# STM32MP21_CA35 register map
File version: 0.4
CPU: CM33 r0p1, little endian, MPU, FPU, vendor SysTick, 8 interrupt priority bits
Registers are 32-bit, read-write, reset 0x0 unless marked. A register's access mark holds for its fields unless they carry their own. Offsets are from the block's base; [hi:lo] are bit positions; {n}, {i} and the like mark numbered series; 'fields as' and 'values as' point back to an identical list.

## EXTI1 — EXTI1 address block description
Base 0x44220000
Same registers: EXTI1_S 0x54220000
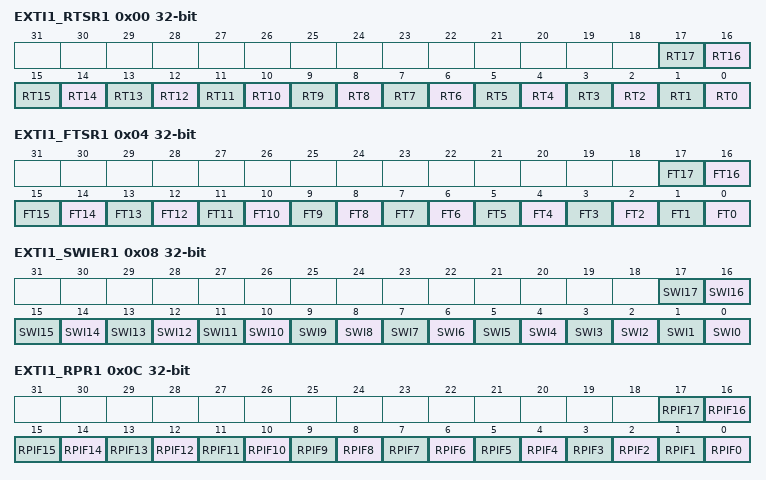
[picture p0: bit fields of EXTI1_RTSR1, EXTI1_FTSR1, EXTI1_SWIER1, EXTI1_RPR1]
0x00 EXTI1_RTSR1 — EXTI1 rising trigger selection register
  [all] fields
    0=Rising trigger disabled (for event and interrupt) for input line; 1=Rising trigger enabled (for event and interrupt) for input line
  [n] RT{n} (n=0..17) — Rising trigger event configuration bit of configurable event input x
0x04 EXTI1_FTSR1 — EXTI1 falling trigger selection register
  [all] fields
    0=Falling trigger disabled (for event and interrupt) for input line; 1=Falling trigger enabled (for event and interrupt) for input line
  [n] FT{n} (n=0..17) — Falling trigger event configuration bit of configurable event input x
0x08 EXTI1_SWIER1 — EXTI1 software interrupt event register
  [all] fields
    0=Writing 0 has no effect; 1=Writing 1 to this bit triggers a rising edge event on event x (bit auto cleared byhardware)
  [n] SWI{n} (n=0..17) — Software interrupt on event x
0x0C EXTI1_RPR1 — EXTI1 rising edge pending register
  [all] fields
    0=No rising edge trigger request occurred; 1=Rising edge trigger request occurred
  [n] RPIF{n} (n=0..17) — Configurable event input x rising edge pending bit
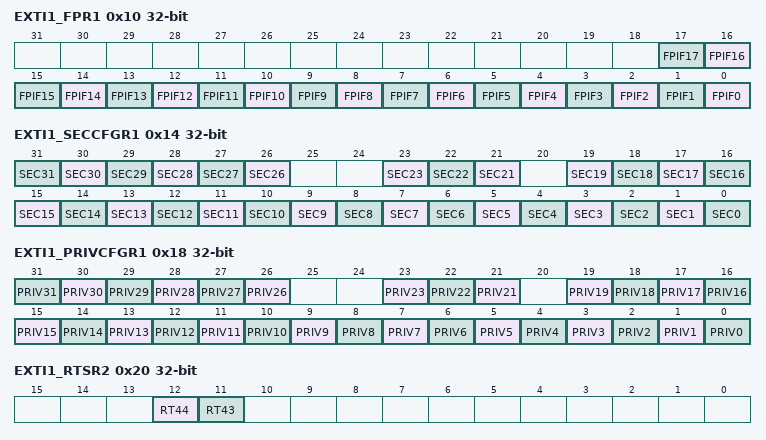
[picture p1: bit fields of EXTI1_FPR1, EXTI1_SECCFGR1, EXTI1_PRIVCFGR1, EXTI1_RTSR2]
0x10 EXTI1_FPR1 — EXTI1 falling edge pending register
  [all] fields
    0=No falling edge trigger request occurred; 1=Falling edge trigger request occurred
  [n] FPIF{n} (n=0..17) — configurable event input x falling edge pending bit
0x14 EXTI1_SECCFGR1 — EXTI1 security configuration register
  [n] SEC{n} (n=26..31) — Security enable on event input x
    0=Event security disabled (non-secure); 1=Event security enabled (secure)
  [23] SEC23 — Security enable on event input x
  [22] SEC22 — Security enable on event input x
  [21] SEC21 — Security enable on event input x
  [n] SEC{n} (n=0..19) — Security enable on event input x
0x18 EXTI1_PRIVCFGR1 — EXTI1 privilege configuration register
  [n] PRIV{n} (n=26..31) — Privilege enable on event input x
    0=Event privilege disabled (unprivileged); 1=Event privilege enabled (privileged)
  [23] PRIV23 — Privilege enable on event input x
  [22] PRIV22 — Privilege enable on event input x
  [21] PRIV21 — Privilege enable on event input x
  [n] PRIV{n} (n=0..19) — Privilege enable on event input x
0x20 EXTI1_RTSR2 — EXTI1 rising trigger selection register
  [12] RT44 — Rising trigger event configuration bit of configurable event input x
    0=Rising trigger disabled (for event and Interrupt) for input line x; 1=Rising trigger enabled (for event and Interrupt) for input line x
  [11] RT43 — Rising trigger event configuration bit of configurable event input x
    values as RT44
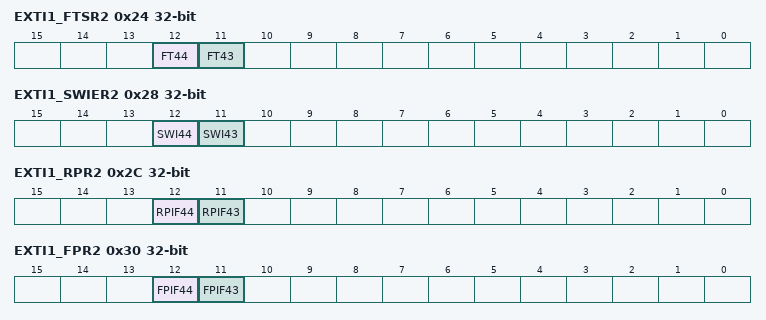
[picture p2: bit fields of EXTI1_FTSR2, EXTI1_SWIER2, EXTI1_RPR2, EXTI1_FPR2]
0x24 EXTI1_FTSR2 — EXTI1 falling trigger selection register
  [12] FT44 — Falling trigger event configuration bit of configurable event input x
    0=Falling trigger disabled (for event and Interrupt) for input line; 1=Falling trigger enabled (for event and Interrupt) for input line
  [11] FT43 — Falling trigger event configuration bit of configurable event input x
    values as FT44
0x28 EXTI1_SWIER2 — EXTI1 software interrupt event register
  [12] SWI44 — Software interrupt on event x
    0=Writing 0 has no effect; 1=Writing 1 to this bit triggers a rising edge event on event x (bit auto cleared by hardware)
  [11] SWI43 — Software interrupt on event x
    values as SWI44
0x2C EXTI1_RPR2 — EXTI1 rising edge pending register
  [12] RPIF44 — Configurable event input x rising edge pending bit
    values as the fields of EXTI1_RPR1
  [11] RPIF43 — Configurable event input x rising edge pending bit
    values as the fields of EXTI1_RPR1
0x30 EXTI1_FPR2 — EXTI1 falling edge pending register
  [12] FPIF44 — Configurable event input x falling edge pending bit
    values as the fields of EXTI1_FPR1
  [11] FPIF43 — Configurable event input x falling edge pending bit
    values as the fields of EXTI1_FPR1
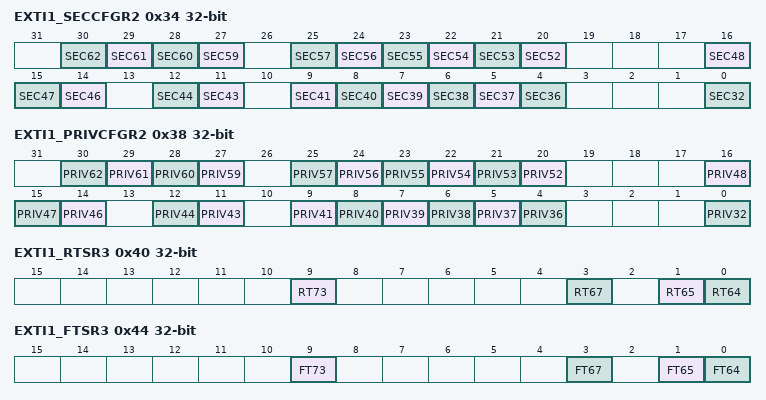
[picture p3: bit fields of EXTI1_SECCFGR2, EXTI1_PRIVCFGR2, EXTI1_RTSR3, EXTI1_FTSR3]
0x34 EXTI1_SECCFGR2 — EXTI1 security enable register
  [n-32] SEC{n} (n=59..62) — Security enable on event input x
    values as EXTI1_SECCFGR1.SEC26
  [n-32] SEC{n} (n=52..57) — Security enable on event input x
  [16] SEC48 — Security enable on event input x
  [15] SEC47 — Security enable on event input x
  [14] SEC46 — Security enable on event input x
  [12] SEC44 — Security enable on event input x
  [11] SEC43 — Security enable on event input x
  [n-32] SEC{n} (n=36..41) — Security enable on event input x
  [0] SEC32 — Security enable on event input 32
0x38 EXTI1_PRIVCFGR2 — EXTI1 privilege enable register
  [n-32] PRIV{n} (n=59..62) — Privilege enable on event input x
    values as EXTI1_PRIVCFGR1.PRIV26
  [n-32] PRIV{n} (n=52..57) — Privilege enable on event input x
  [16] PRIV48 — Privilege enable on event input x
  [15] PRIV47 — Privilege enable on event input x
  [14] PRIV46 — Privilege enable on event input x
  [12] PRIV44 — Privilege enable on event input x
  [11] PRIV43 — Privilege enable on event input x
  [n-32] PRIV{n} (n=36..41) — Privilege enable on event input x
  [0] PRIV32 — Privilege enable on event input 32
0x40 EXTI1_RTSR3 — EXTI1 rising trigger selection register
  [9] RT73 — Rising trigger event configuration bit of configurable event input 73
    values as the fields of EXTI1_RTSR1
  [3] RT67 — Rising trigger event configuration bit of configurable event input 67
  [1] RT65 — Rising trigger event configuration bit of configurable event input x
  [0] RT64 — Rising trigger event configuration bit of configurable event input x
0x44 EXTI1_FTSR3 — EXTI1 falling trigger selection register
  [9] FT73 — Falling trigger event configuration bit of configurable event input 73
    values as the fields of EXTI1_FTSR1
  [3] FT67 — Falling trigger event configuration bit of configurable event input 67
  [1] FT65 — Falling trigger event configuration bit of configurable event input x
  [0] FT64 — Falling trigger event configuration bit of configurable event input x
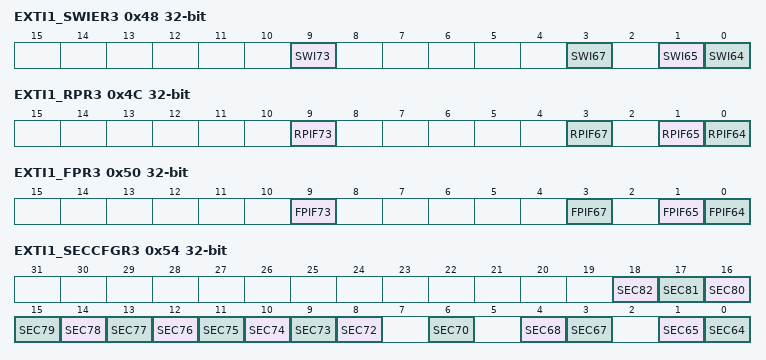
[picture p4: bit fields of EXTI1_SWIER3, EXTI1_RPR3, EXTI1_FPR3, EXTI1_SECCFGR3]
0x48 EXTI1_SWIER3 — EXTI1 software interrupt event register
  [9] SWI73 — Software interrupt on event 73
    values as EXTI1_SWIER2.SWI44
  [3] SWI67 — Software interrupt on event 67.
  [1] SWI65 — Software interrupt on event x
  [0] SWI64 — Software interrupt on event x
0x4C EXTI1_RPR3 — EXTI1 rising edge pending register
  [9] RPIF73 — configurable event input 73 rising edge pending bit
    values as the fields of EXTI1_RPR1
  [3] RPIF67 — configurable event input 67 rising edge pending bit
  [1] RPIF65 — configurable event input x rising edge pending bit
  [0] RPIF64 — configurable event input x rising edge pending bit
0x50 EXTI1_FPR3 — EXTI1 falling edge pending register
  [9] FPIF73 — configurable event input 73 falling edge pending bit
    values as the fields of EXTI1_FPR1
  [3] FPIF67 — configurable 67 falling edge pending bit
  [1] FPIF65 — configurable event input x falling edge pending bit
  [0] FPIF64 — configurable event input x falling edge pending bit
0x54 EXTI1_SECCFGR3 — EXTI1 security enable register
  [n-64] SEC{n} (n=72..82) — Security enable on event input x
    values as EXTI1_SECCFGR1.SEC26
  [6] SEC70 — Security enable on event input 70
  [4] SEC68 — Security enable on event input x
  [3] SEC67 — Security enable on event input x
  [1] SEC65 — Security enable on event input x
  [0] SEC64 — Security enable on event input x
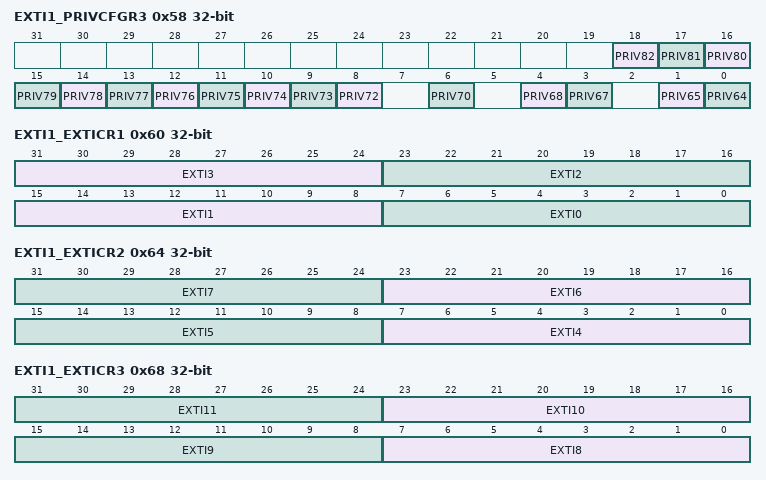
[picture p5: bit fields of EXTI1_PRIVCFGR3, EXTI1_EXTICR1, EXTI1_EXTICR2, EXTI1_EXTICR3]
0x58 EXTI1_PRIVCFGR3 — EXTI1 privilege enable register
  [n-64] PRIV{n} (n=72..82) — Privilege enable on event input x
    0=Event privilege disabled (unprivileged; 1=Event privilege enabled (privileged)
  [6] PRIV70 — Privilege enable on event input 70
  [4] PRIV68 — Privilege enable on event input x
  [3] PRIV67 — Privilege enable on event input x
  [1] PRIV65 — Privilege enable on event input x
  [0] PRIV64 — Privilege enable on event input x
0x60 EXTI1_EXTICR1 — EXTI1 external interrupt selection register 1
  [31:24] EXTI3 — EXTI3 GPIO port selection
    0=PA3 pin; 1=PB3 pin; 2=PC3 pin; 3=PD3 pin; 4=PE3 pin; 5=PF3 pin; 6=PG3 pin; 7=PH3 pin; 8=PI3 pin; 9=PZ3 pin
  [23:16] EXTI2 — EXTI2 GPIO port selection
    0=PA2 pin; 1=PB2 pin; 2=PC2 pin; 3=PD2 pin; 4=PE2 pin; 5=PF2 pin; 6=PG2 pin; 7=PH2 pin; 8=PI2 pin; 9=PZ2 pin
  [15:8] EXTI1 — EXTI1 GPIO port selection
    0=PA1 pin; 1=PB1 pin; 2=PC1 pin; 3=PD1 pin; 4=PE1 pin; 5=PF1 pin; 6=PG1 pin; 7=PH1 pin; 8=PI1 pin; 9=PZ1 pin
  [7:0] EXTI0 — EXTI0 GPIO port selection.
    0=PA0 pin; 1=PB0 pin; 2=PC0 pin; 3=PD0 pin; 4=PE0 pin; 5=PF0 pin; 6=PG0 pin; 7=PH0 pin; 8=PI0 pin; 9=PZ0 pin
0x64 EXTI1_EXTICR2 — EXTI1 external interrupt selection register 2
  [8n-25:8n-32] EXTI{n} (n=4..7) — EXTI{n} GPIO port selection.
    0=PA{n} pin; 1=PB{n} pin; 2=PC{n} pin; 3=PD{n} pin; 4=PE{n} pin; 5=PF{n} pin; 6=PG{n} pin; 7=PH{n} pin; 8=PI{n} pin; 9=PZ{n} pin
0x68 EXTI1_EXTICR3 — EXTI1 external interrupt selection register 3
  [8n-57:8n-64] EXTI{n} (n=8..11) — EXTI{n} GPIO port selection.
    values as EXTI1_EXTICR2.EXTI4
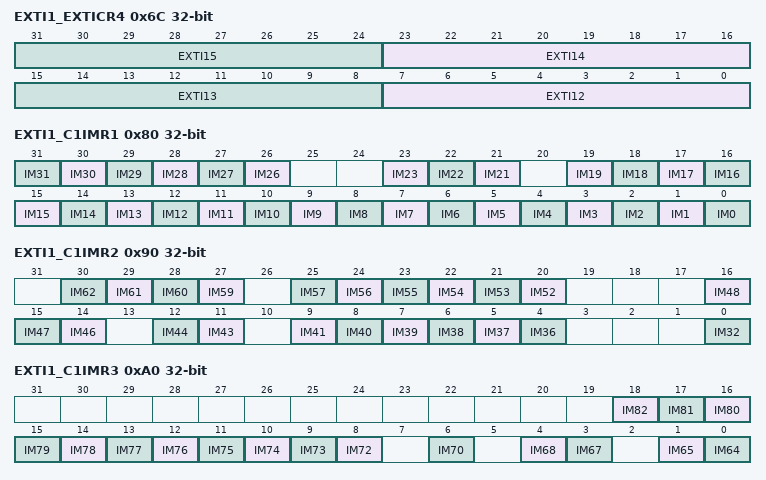
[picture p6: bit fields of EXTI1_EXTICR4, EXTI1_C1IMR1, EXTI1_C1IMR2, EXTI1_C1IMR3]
0x6C EXTI1_EXTICR4 — EXTI1 external interrupt selection register 4
  [8n-89:8n-96] EXTI{n} (n=12..15) — EXTI{n} GPIO port selection.
    values as EXTI1_EXTICR2.EXTI4
0x70 EXTI1_LOCKR — EXTI1 lock register
  [0] GLOCK — Global security privilege and CID configuration registers EXTI1_SECCFGRx, EXTI1_PRIVCFGRx,EXTI1_EnCIDCFGR and EXTI1_CmCIDCFGR lock.
    0=Security, privilege, and CID configuration open can be modified; 1=Security, privilege, and CID configuration locked can no longer be modified
0x80 EXTI1_C1IMR1 — EXTI1 CPU1 wake-up with interrupt mask register
  [n] IM{n} (n=26..31) — CPUm wake-up with interrupt mask on event input x
    0=Wake-up and interrupt CPU(m) from input event x is masked; 1=Wake-up and interrupt CPU(m) from input event x is unmasked
  [23] IM23 — CPUm wake-up with interrupt mask on event input x
  [22] IM22 — CPUm wake-up with interrupt mask on event input x
  [21] IM21 — CPUm wake-up with interrupt mask on event input x
  [n] IM{n} (n=0..19) — CPUm wake-up with interrupt mask on event input x
0x90 EXTI1_C1IMR2 — EXTI1 CPU1 wake-up with interrupt mask register
  [n-32] IM{n} (n=59..62) — CPUm wake-up with interrupt mask on event input x
    values as EXTI1_C1IMR1.IM26
  [n-32] IM{n} (n=52..57) — CPUm wake-up with interrupt mask on event input x
  [16] IM48 — CPUm wake-up with interrupt mask on event input x
  [15] IM47 — CPUm wake-up with interrupt mask on event input x
  [14] IM46 — CPUm wake-up with interrupt mask on event input x
  [12] IM44 — CPUm wake-up with interrupt mask on event input x
  [11] IM43 — CPUm wake-up with interrupt mask on event input x
  [n-32] IM{n} (n=36..41) — CPUm wake-up with interrupt mask on event input x
  [0] IM32 — CPUm wake-up with interrupt mask on event input 32
0xA0 EXTI1_C1IMR3 — EXTI1 CPU1 wake-up with interrupt mask register
  [n-64] IM{n} (n=72..82) — CPUm wake-up with interrupt mask on event input x
    values as EXTI1_C1IMR1.IM26
  [6] IM70 — CPUm wake-up with interrupt mask on event input 70.
  [4] IM68 — CPUm wake-up with interrupt mask on event input x
  [3] IM67 — CPUm wake-up with interrupt mask on event input x
  [1] IM65 — CPUm wake-up with interrupt mask on event input x
  [0] IM64 — CPUm wake-up with interrupt mask on event input x
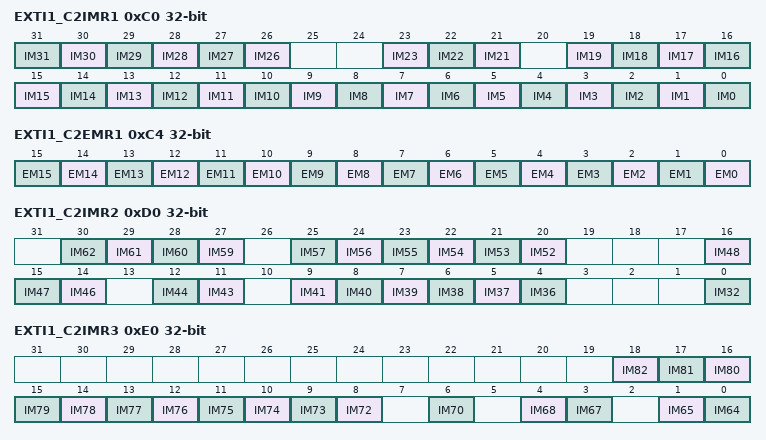
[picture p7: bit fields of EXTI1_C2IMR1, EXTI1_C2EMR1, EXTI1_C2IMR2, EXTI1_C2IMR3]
0xC0 EXTI1_C2IMR1 — EXTI1 CPU2 wake-up with interrupt mask register
  fields as EXTI1_C1IMR1
0xC4 EXTI1_C2EMR1 — EXTI1 CPU2 wake-up with event mask register
  [all] fields
    0=Wake-up with event request from line x is masked; 1=Wake-up with event request from line x is unmasked
  [n] EM{n} (n=0..15) — CPU2 wake-up with event on event input x
0xD0 EXTI1_C2IMR2 — EXTI1 CPU2 wake-up with interrupt mask register
  fields as EXTI1_C1IMR2
0xE0 EXTI1_C2IMR3 — EXTI1 CPU2 wake-up with interrupt mask register
  fields as EXTI1_C1IMR3
0xE4 EXTI1_C2EMR3 — EXTI1 CPU2 wake-up with event mask register
  [1] EM65 — CPU2 wake-up with event mask on event input 65
    0=Wake-up with event request from line 65 is masked; 1=Wake-up with event request from line 65 is unmasked
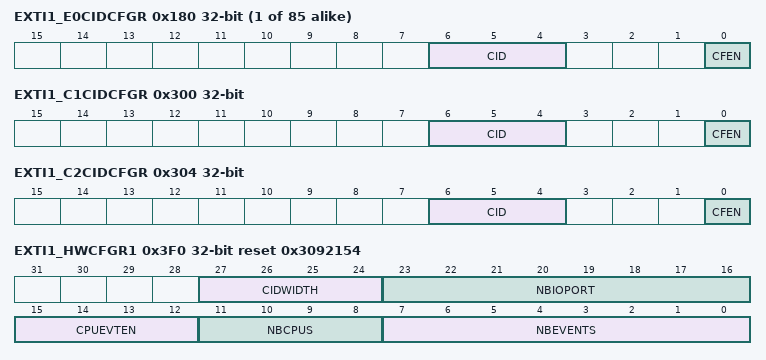
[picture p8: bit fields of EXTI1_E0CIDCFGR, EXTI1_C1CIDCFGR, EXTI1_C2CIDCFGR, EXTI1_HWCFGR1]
{0x180+4i} EXTI1_E{i}CIDCFGR (i=0..84) — EXTI1 event CID configuration register
  [6:4] CID — EXTI event n allowed CID value
  [0] CFEN — EXTI event n CID filtering enable
    0=Disable EXTI event n filtering (EXTI event n can be accessed by any CIDs); 1=Enable EXTI event n filtering (EXTI event n can only be accessed by the processor with CID = CPUm CID)
0x300 EXTI1_C1CIDCFGR — EXTI1 processor 1 CID configuration register
  [6:4] CID — CPUm CID domain identification
  [0] CFEN — CID filtering enabled for CPUm EXTI1_CmIMRx and EXTI1_CmEMRx registers
    0=Disable the CID filtering for CPUm; 1=Enable the CID filtering for CPUm
0x304 EXTI1_C2CIDCFGR — EXTI1 processor 2 CID configuration register
  fields as EXTI1_C1CIDCFGR
0x3C0 EXTI1_HWCFGR13 ro reset 0x7FF5B — EXTI1 hardware configuration registers 13
  [31:0] SEC — Hardware configuration event security privilege and resource isolation capability
    0=Non-secure, unprivileged, and no resource filtering event; 1=Security, privileged, and resource filtering capable event
0x3C4 EXTI1_HWCFGR12 ro reset 0x7BF1DBF1 — EXTI1 hardware configuration registers 12
  fields as EXTI1_HWCFGR13
0x3C8 EXTI1_HWCFGR11 ro reset 0xFCEFFFFF — EXTI1 hardware configuration registers 11
  fields as EXTI1_HWCFGR13
0x3D8 EXTI1_HWCFGR7 ro reset 0x2 — EXTI1 hardware configuration registers 7
  [31:0] CPUEVENT — Hardware configuration CPU event generation
    0=No CPU event generated; 1=CPU event generated
0x3DC EXTI1_HWCFGR6 ro — EXTI1 hardware configuration registers 6
  fields as EXTI1_HWCFGR7
0x3E0 EXTI1_HWCFGR5 ro reset 0xFFFF — EXTI1 hardware configuration registers 5
  fields as EXTI1_HWCFGR7
0x3E4 EXTI1_HWCFGR4 ro reset 0x20B — EXTI1 hardware configuration registers 4
  [31:0] EVENT_TRG — Hardware configuration event trigger type
    0=Direct event; 1=Configurable event
0x3E8 EXTI1_HWCFGR3 ro reset 0x1800 — EXTI1 hardware configuration registers 3
  fields as EXTI1_HWCFGR4
0x3EC EXTI1_HWCFGR2 ro reset 0x3FFFF — EXTI1 hardware configuration registers 2
  fields as EXTI1_HWCFGR4
0x3F0 EXTI1_HWCFGR1 ro reset 0x3092154 — EXTI1 hardware configuration register 1
  [27:24] CIDWIDTH — CID parameters bit width
  [23:16] NBIOPORT — Hardware configuration of number of I/O ports on EXTI (n+1)
  [15:12] CPUEVTEN — Hardware configuration of CPU(m) event output enable.
  [11:8] NBCPUS — Hardware configuration number of CPUs (n+1)
  [7:0] NBEVENTS — Hardware configuration number of event (n+1)
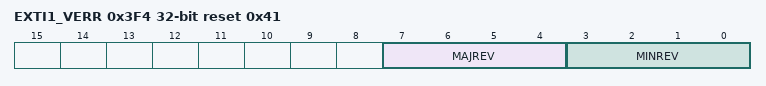
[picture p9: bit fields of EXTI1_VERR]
0x3F4 EXTI1_VERR ro reset 0x41 — EXTI1 version register
  [7:4] MAJREV — Major revision number
  [3:0] MINREV — Minor revision number
0x3F8 EXTI1_IPIDR ro reset 0xE0001 — EXTI1 identification register
  [31:0] IPID — EXTI1 identification
0x3FC EXTI1_SIDR ro reset 0xA3C5DD01 — EXTI1 size identification register
  [31:0] SID — Size identification
